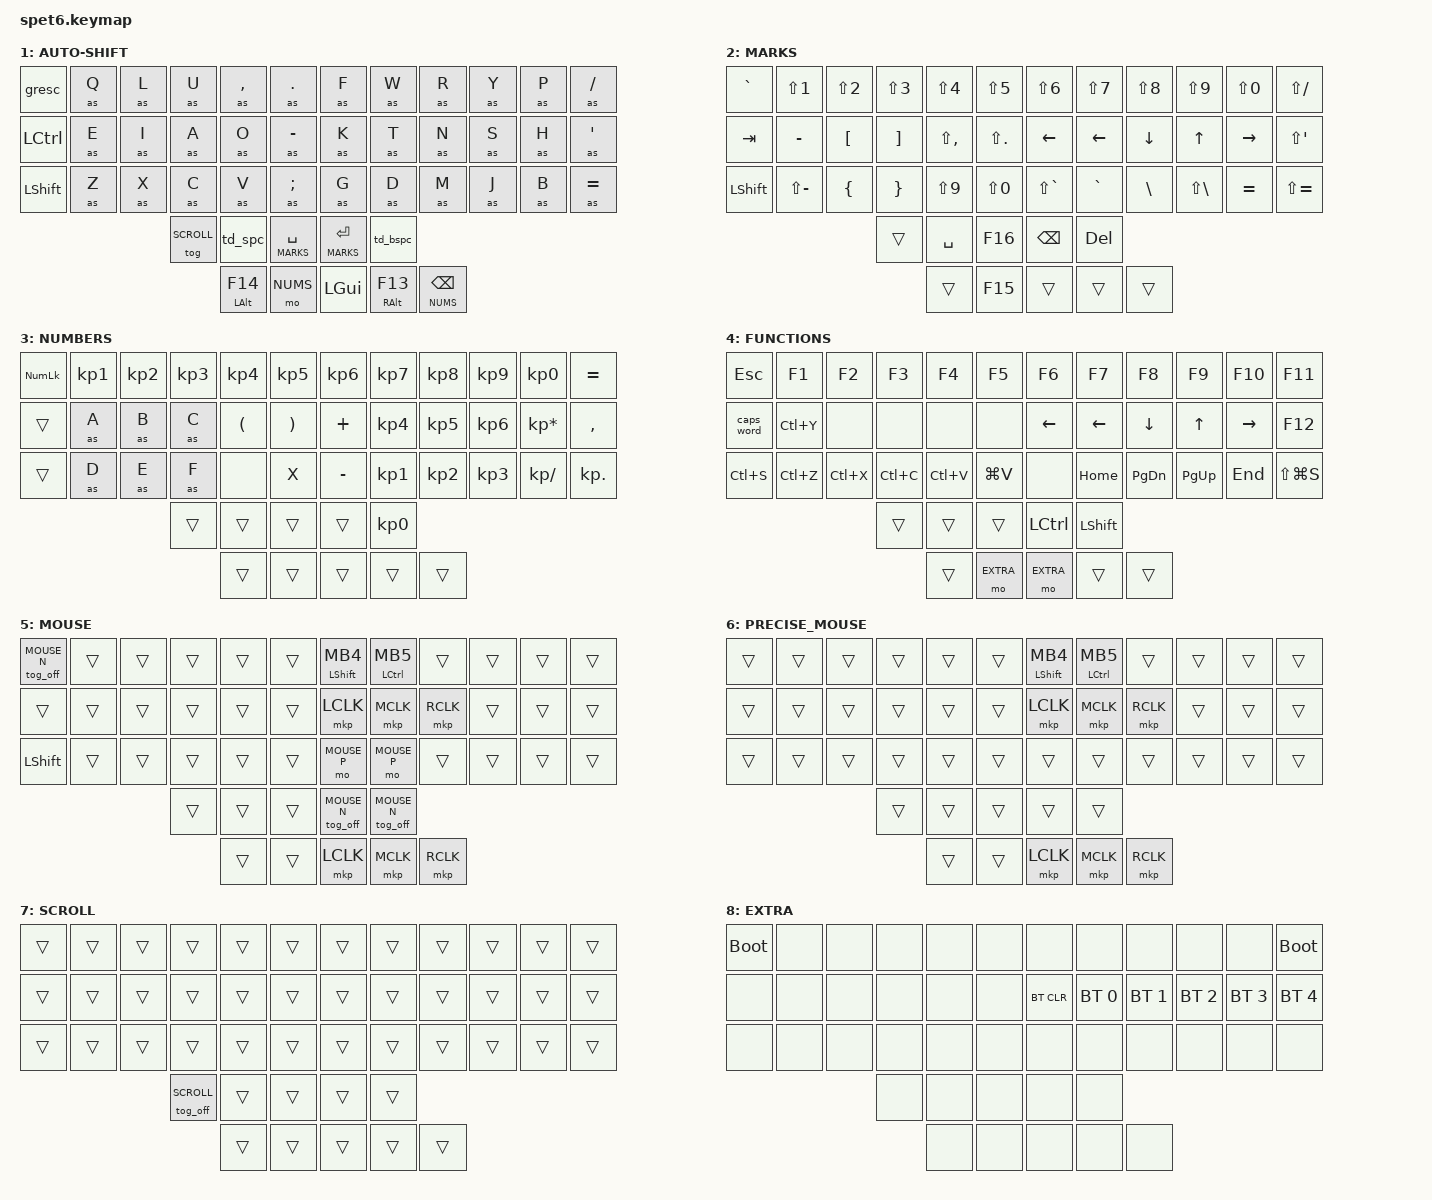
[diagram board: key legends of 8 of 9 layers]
/*
 * Copyright (c) 2020 The ZMK Contributors
 *
 * SPDX-License-Identifier: MIT
 */

#include <input/processors.dtsi>

#define ZMK_POINTING_DEFAULT_SCRL_VAL 120
#define ZMK_MOUSE_SCRL_VAL 140

#include <zephyr/dt-bindings/input/input-event-codes.h>
#include <behaviors.dtsi>
#include <dt-bindings/zmk/bt.h>
#include <dt-bindings/zmk/keys.h>
#include <dt-bindings/zmk/pointing.h>

#define DEFAULT   0
#define AUTOSHIFT 1
#define MARKS     2
#define NUMS      3
#define FUNCS     4
#define MOUSE_N   5
#define MOUSE_P   6
#define SCROLL    7
#define EXTRA     8

// OS設定を日本語キーボードのまま使用するための変換定義
#define JP_DQUOTE       AT                // "
#define JP_AMPERSAND    CARET             // &
#define JP_QUOTE        AMPERSAND         // '
#define JP_EQUAL        UNDER             // =
#define JP_CARET        EQUAL             // ^
#define JP_YEN          0x89              // ¥
#define JP_PLUS         COLON             // +
#define JP_TILDE        PLUS              // ~
#define JP_PIPE         LS(0x89)          // |
#define JP_AT           LEFT_BRACKET      // @
#define JP_COLON        SINGLE_QUOTE      // :
#define JP_ASTERISK     DOUBLE_QUOTES     // *
#define JP_BACKQUOTE    LEFT_BRACE        // `
#define JP_UNDERSCORE   LS(0x87)          // _
#define JP_LBRACKET     RIGHT_BRACKET     // [
#define JP_RBRACKET     BACKSLASH         // ]
#define JP_LPAREN       ASTERISK          // (
#define JP_RPAREN       LEFT_PARENTHESIS  // )
#define JP_LBRACE       RIGHT_BRACE       // {
#define JP_RBRACE       PIPE              // }
#define JP_KANA         LANGUAGE_1        // かな
#define JP_EISU         LANGUAGE_2        // 英数
#define JP_HANZEN       GRAVE             // 半角/全角

/**************************************************************************/
/*  TrackBall 関連                                                        */

&trackball { cpi = <600>; };

&trackball_listener {
    input-processors = <&zip_temp_layer MOUSE_N 5000>;

    precise {
        layers = <MOUSE_P>;
        input-processors = <&zip_xy_scaler 1 16>;
        process-next;
    };
};

&trackball_scroller {
    layers = <SCROLL>;

    // Example: adjust sensitivity of scroll multiply by 1 and divide by 60.
    // input-processors = <&zip_xy_scaler 1 60 &zip_xy_to_scroll_mapper>;
};

// クリック時に10秒間AMLを延長

&mkp_input_listener { input-processors = <&zip_temp_layer MOUSE_N 10000>; };

// キー入力から200ms間はAMLを抑制(AML誤発動防止)

&zip_temp_layer { require-prior-idle-ms = <200>; };

/**************************************************************************/
/*   マウススクロール用設定                                               */

/ {
    input_processors {
        zip_wheel_scaler: zip_wheel_scaler {
            compatible = "zmk,input-processor-scaler";
            #input-processor-cells = <2>;
            type = <INPUT_EV_REL>;
            codes = <INPUT_REL_WHEEL>;
            track-remainders;
        };
    };
};

&msc {
    delay-ms = <0>;
    trigger-period-ms = <10>;
    time-to-max-speed-ms = <0>;
    acceleration-exponent = <0>;
};

&msc_input_listener {
    warp {
        layers = <MOUSE_N SCROLL>;
        input-processors = <&zip_wheel_scaler 4 1>;
    };

    normal {
        layers = <DEFAULT MARKS NUMS FUNCS EXTRA>;
        input-processors = <&zip_wheel_scaler 1 1>;
    };
};

/**************************************************************************/

/ {
    combos {
        compatible = "zmk,combos";

        combo_shift_R {
            bindings = <&kp RSHFT>;
            key-positions = <39 40>;
        };

        combo_shift_L {
            bindings = <&kp LSHFT>;
            key-positions = <37 38>;
        };

        combo_tab {
            bindings = <&kp TAB>;
            key-positions = <12 13>;
        };

        mo_scroll {
            bindings = <&mo SCROLL>;
            key-positions = <41 42>;
        };

        mo_scroll2 {
            bindings = <&mo SCROLL>;
            key-positions = <30 31>;
        };

        alt_space {
            bindings = <&kp LA(SPACE)>;
            key-positions = <38 39>;
        };

        combo_capslock {
            bindings = <&kp CAPS>;
            key-positions = <12 13 14>;
        };

        toggle_autoshift {
            bindings = <&tog AUTOSHIFT>;
            key-positions = <0 11>;
        };

        Lctrl {
            bindings = <&kp LCTRL>;
            key-positions = <24 25>;
        };

        Rctrl {
            bindings = <&kp RCTRL>;
            key-positions = <34 35>;
        };

        toggle_IME {
            bindings = <&kp LC(SPACE)>;
            key-positions = <37 40>;
        };
    };

    /**************************************************************************/

    macros {
        // for Auto Shift

        shifted: macro_shifted_kp {
            #binding-cells = <1>;
            label = "MACRO_SHIFTED_KP";
            compatible = "zmk,behavior-macro-one-param";
            bindings =
                <&macro_press>,
                <&kp LSHFT &macro_param_1to1>,
                <&macro_tap>,
                <&kp MACRO_PLACEHOLDER>,
                <&macro_release>,
                <&kp LSHFT>;
        };

        as: autoshift {
            compatible = "zmk,behavior-macro-one-param";
            #binding-cells = <1>;
            label = "AUTOSHIFT_KP";
            bindings =
                <&macro_press>,
                <&macro_param_1to1 &macro_param_1to2 &as_ht MACRO_PLACEHOLDER MACRO_PLACEHOLDER>,
                <&macro_pause_for_release>,
                <&macro_release>,
                <&macro_param_1to1 &macro_param_1to2 &as_ht MACRO_PLACEHOLDER MACRO_PLACEHOLDER>;
        };
    };

    /**************************************************************************/

    behaviors {
        td_bspc: tap_dance_0 {
            compatible = "zmk,behavior-tap-dance";
            #binding-cells = <0>;
            tapping-term-ms = <200>;
            bindings = <&lt FUNCS BSPC>, <&kp BSPC>;
        };

        td_spc: tap_dance_1 {
            compatible = "zmk,behavior-tap-dance";
            #binding-cells = <0>;
            tapping-term-ms = <200>;
            bindings = <&lt FUNCS SPACE>, <&kp SPACE>;
        };

        mouse_scroll: mouse_wheel_scroll {
            compatible = "zmk,behavior-sensor-rotate-var";
            #sensor-binding-cells = <2>;
            bindings = <&msc>, <&msc>;

            tap-ms = <25>;
        };

        mod_mkp: mod_mkp {
            compatible = "zmk,behavior-hold-tap";
            label = "MOD_MKP";
            bindings = <&kp>, <&mkp>;

            #binding-cells = <2>;
            tapping-term-ms = <150>;
        };

        as_ht: autoshift_hold_tap {
            compatible = "zmk,behavior-hold-tap";
            label = "AUTOSHIFT_HOLD_TAP";
            #binding-cells = <2>;
            tapping_term_ms = <180>;
            quick_tap_ms = <0>;
            flavor = "tap-preferred";
            bindings = <&shifted>, <&kp>;
        };

        tog_off: toggle_layer_off {
            compatible = "zmk,behavior-toggle-layer";
            #binding-cells = <1>;
            display-name = "Toggle Layer Off";
            toggle-mode = "off";
        };

        ime_alt: ime_alt {
            compatible = "zmk,behavior-hold-tap";
            label = "IME_ALT";
            bindings = <&kp>, <&kp>;

            #binding-cells = <2>;
            tapping-term-ms = <200>;
            flavor = "tap-preferred";
        };
    };

    /**************************************************************************/

    keymap {
        compatible = "zmk,keymap";

        default_layer {
            display-name = "BASE";

            //               | SW2  | SW3  | SW4  | SW5  |   | SW6  | SW7  | SW8  | SW9  |
            // | SW0  | SW1  | SW14 | SW15 | SW16 | SW17 |   | SW18 | SW19 | SW20 | SW21 | SW10 | SW11 |
            // | SW12 | SW13 | SW26 | SW27 | SW28 | SW29 |   | SW30 | SW31 | SW32 | SW33 | SW22 | SW23 |
            // | SW24 | SW25 | SW38 | SW39 | SW40 | SW41 |   | SW42 | SW43 | SW44 | SW45 | SW34 | SW35 |
            // | SW36 | SW37 | SW50 | SW51 | SW52 | SW53 |   | SW54 | SW55 | SW56 | SW57 | SW46 | SW47 |
            // | SW48 | SW49 | SW60 | SW61 | SW62 | (LAJS)   (RAJS) | SW69 | SW70 | SW71 | SW58 | SW59 |
            //                                  (TouchPad)
            // 		                              | SW65 |   | SW66 |	    (TrackBall)
            // 							   | SW64 |					| SW67 |
            // | SW72 |				| SW63 |							   | SW68 |				| SW83 |
            //    (LeftRotaryEncoder)                                             (RightRotaryEncoder)
            //		  | SW73 |															 | SW78 |
            // | SW74 | SW77 | SW76 |											  | SW79 | SW82 | SW81 |
            // 		  | SW75 |															 | SW80 |

//                                                         ||
//                                                       __||__
//                                                        \  /
//                                                         \/

            // | SW0  | SW1  | SW2  | SW3  | SW4  | SW5  |   | SW6  | SW7  | SW8  | SW9  | SW10 | SW11 |
            // | SW12 | SW13 | SW14 | SW15 | SW16 | SW17 |   | SW18 | SW19 | SW20 | SW21 | SW22 | SW23 |
            // | SW24 | SW25 | SW26 | SW27 | SW28 | SW29 |   | SW30 | SW31 | SW32 | SW33 | SW34 | SW35 |
            // | SW36 | SW37 | SW38 | SW39 | SW40 | SW41 |   | SW42 | SW43 | SW44 | SW45 | SW46 | SW47 |
            // | SW48 | SW49 | SW50 | SW51 | SW52 | SW53 |   | SW54 | SW55 | SW56 | SW57 | SW58 | SW59 |
            // | SW60 | SW61 | SW62 | SW63 | SW64 | SW65 |   | SW66 | SW67 | SW68 | SW69 | SW70 | SW71 |
            // | SW72 | SW73 | SW74 | SW75 | SW76 | SW77 |   | SW78 | SW79 | SW80 | SW81 | SW82 | SW83 |

                                                          

            // -----------------------------------------------------------------------------------------
            //               |  F4  |  F5  |  F6  |  F7  |   |  F8  |  F9  | F10  | F11  |
            // | ESCP | HOME |   2  |   3  |   4  |   5  |   |   6  |   7  |   8  |   9  |  END |  DEL |
            // |  E/J |   1  |   W  |   E  |   R  |   T  |   |   Y  |   U  |   I  |   O  |   0  | BKSP |
            // |  TAB |   Q  |   S  |   D  |   F  |   G  |   |   H  |   J  |   K  |   L  |   P  | ENTR |
            // | LSft |   A  |   X  |   C  |   V  |   B  |   |   N  |   M  |   ,  |   .  |   ↑  | RSft |
            // | LAlt |   Z  |  GUI | LCtr | SPCE |                 | SPCE | RCtr |   ←  |   ↓  |   →  |
            // 		                      	
            //                                    | SPCE |   | SPCE |
            // 							   | ENTR |					| ENTR |
            // | layr |				| BKSP |							   | BKSP |				| layr |
            //
            //		  | CtrC |															 | CtrT |
            // | CtrZ | Entr | CtrY |											  | BTab | Entr | NTab |
            // 		  | CtrV |															 | CtrW |

            // -----------------------------------------------------------------------------------------
            // | ESCP | HOME |  F4  |  F5  |  F6  |  F7  |   |  F8  |  F9  | F10  | F11  |  END |  DEL |
            // |  E/J |   1  |   2  |   3  |   4  |   5  |   |   6  |   7  |   8  |   9  |   0  | BKSP |
            // |  TAB |   Q  |   W  |   E  |   R  |   T  |   |   Y  |   U  |   I  |   O  |   P  | ENTR |
            // | LSft |   A  |   S  |   D  |   F  |   G  |   |   H  |   J  |   K  |   L  |   ↑  | RSft |
            // | LAlt |   Z  |   X  |   C  |   V  |   B  |   |   N  |   M  |   ,  |   .  |   ↓  |   →  |
            // |  GUI | LCtr | SPCE | BKSP | ENTR | SPCE |   | SPCE | ENTR | BKSP | SPCE | RCtr |   ←  |
            // | layr | CtrC | CtrZ | CtrV | CtrY | Entr |   | CtrT | BTab | CtrW | NTab | CtrT | layr |

            bindings = <
&gresc         &kp HOME   &kp F4     &kp F5         &kp F6          &kp F7       &kp F8         &kp F9             &kp F10        &kp F11     &kp END    &kp DEL
&kp JP_HANZEN  &kp 1      &kp 2      &kp 3          &kp 4           &kp 5        &kp 6          &kp 7              &kp 8          &kp 9       &kp 0      &kp BACKSPACE
&kp TAB        &kp Q      &kp W      &kp E          &kp R           &kp T        &kp Y          &kp U              &kp I          &kp O       &kp P      &kp ENTER
&kp LSHFT      &kp A      &kp S      &kp D          &kp F           &kp G        &kp H          &kp J              &kp K          &kp L       &kp UP     &kp RSHFT
&kp LALT       &kp Z      &kp X      &kp C          &kp V           &kp B        &kp N          &kp M              &kp COMMA      &kp PERIOD  &kp DOWN   &kp RIGHT
&kp LGUI       &kp LCTRL  &kp SPACE  &kp BACKSPACE  &kp ENTER       &kp SPACE    &kp SPACE      &kp ENTER          &kp BACKSPACE  &kp SPACE   &kp RCTRL  &kp LEFT
            >;

            sensor-bindings = <&inc_dec_kp RIGHT LEFT>;
        };

        autoshift_layer {
            display-name = "AUTO-SHIFT";

            // -----------------------------------------------------------------------------------------
            // |  ESC |  Q  |  L  |  U  |  ,  |  .  |   |  F  |  W   |  R  |  Y  |  P  |  /   |
            // | CTRL |  E  |  I  |  A  |  O  |  -  |   |  K  |  T   |  N  |  S  |  H  |  '   |
            // | SHFT |  Z  |  X  |  C  |  V  |  B  |   |  G  |  D   |  M  |  J  |  B  |  =   |
            //        | SCRL| SPC(FUNK) | SPC(MARK) |   | ENT(MARK) | BKSP(FUNC) |
            //              |  LALT     | NUMS      |   | GUI       | RALT       | BKSP(NUM)|

            bindings = <
&gresc     &as Q  &as L  &as U        &as COMMA          &as PERIOD       &as F          &as W              &as R               &as Y  &as P  &as SLASH
&kp LCTRL  &as E  &as I  &as A        &as O              &as MINUS        &as K          &as T              &as N               &as S  &as H  &as SQT
&kp LSHFT  &as Z  &as X  &as C        &as V              &as SEMICOLON    &as G          &as D              &as M               &as J  &as B  &as EQUAL
                         &tog SCROLL  &td_spc            &lt MARKS SPACE  &lt MARKS RET  &td_bspc
                                      &ime_alt LALT F14  &mo NUMS         &kp LGUI       &ime_alt RALT F13  &lt NUMS BACKSPACE
            >;

            sensor-bindings = <&inc_dec_kp RIGHT LEFT>;
        };

        mark_layer {
            display-name = "MARKS";

            // -----------------------------------------------------------------------------------------
            // |  ~   |  !  |  @  |  #  |  $  |  %  |   |  ^  |  &  |  *  |  (        | )   | ?  |
            // | TAB  |  -  |  {  |  }  |  <  | >   |   | LFT | LFT | DWN |  UP       | RGT |  " |
            // |      |  _  |  [  |  ]  |  (  | )   |   |  `  |  ~  |  ¥  |  Lsft(¥)  |  =  |  + |
            //                    | --- |---- | ----|   | ---- | DELETE  |
            //                          |---- | ----|   | ---- |  -----  | ---- |

            bindings = <
&kp GRAVE  &kp LS(N1)     &kp LS(N2)  &kp LS(N3)  &kp LS(N4)     &kp LS(N5)      &kp LS(N6)     &kp LS(N7)  &kp LS(N8)  &kp LS(N9)    &kp LS(N0)  &kp LS(SLASH)
&kp TAB    &kp MINUS      &kp LBKT    &kp RBKT    &kp LS(COMMA)  &kp LS(PERIOD)  &kp LEFT       &kp LEFT    &kp DOWN    &kp UP        &kp RIGHT   &kp LS(SQT)
&kp LSHFT  &kp LS(MINUS)  &kp LBRC    &kp RBRC    &kp LS(N9)     &kp LS(N0)      &kp LS(GRAVE)  &kp GRAVE   &kp BSLH    &kp LS(BSLH)  &kp EQUAL   &kp LS(EQUAL)
                                      &trans      &kp SPACE      &kp F16         &kp BACKSPACE  &kp DELETE
                                                  &trans         &kp F15         &trans         &trans      &trans
            >;

            sensor-bindings = <&inc_dec_kp DOWN UP>;
        };

        num_layer {
            display-name = "NUMBERS";

            // -----------------------------------------------------------------------------------------
            // |  NUM |  1  |  2  |  3  |  4  |  5  |   |  6  |  7  |  8  |  9  |  0  |  .   |
            // | ---- |  a  |  b  |  c  |  (  |  )  |   |  +  |  4  |  5  |  6  |  *  |  ,   |
            // | ---- |  d  |  e  |  f  | --- |  x  |   |  -  |  1  |  2  |  3  |  /  |  =   |
            //                    | --- |---- | ----|   | --- | --- |
            //                          |---- | ----|   | --- | --- | --- |

            bindings = <
&kp KP_NUM  &kp KP_N1  &kp KP_N2  &kp KP_N3  &kp KP_N4             &kp KP_N5              &kp KP_N6  &kp KP_N7        &kp KP_N8  &kp KP_N9  &kp KP_N0        &kp EQUAL
&trans      &as A      &as B      &as C      &kp LEFT_PARENTHESIS  &kp RIGHT_PARENTHESIS  &kp PLUS   &kp KP_N4        &kp KP_N5  &kp KP_N6  &kp KP_ASTERISK  &kp COMMA
&trans      &as D      &as E      &as F      &none                 &kp X                  &kp MINUS  &kp KP_N1        &kp KP_N2  &kp KP_N3  &kp KP_SLASH     &kp KP_DOT
                                  &trans     &trans                &trans                 &trans     &kp KP_NUMBER_0
                                             &trans                &trans                 &trans     &trans           &trans
            >;

            sensor-bindings = <&inc_dec_kp RIGHT LEFT>;
        };

        func_layer {
            display-name = "FUNCTIONS";

            // -----------------------------------------------------------------------------------------
            // |  ESC   | F1   |  F2  |  F3  |  F4   |  F5   |     |  F6 |  F7 |  F8 |  F9 | F10  | F11        |
            // |CAPSWORD| ---  | ---- | ---- | ----- | ----  |     | LEFT| LEFT| DOWN| UP  |RIGHT | F12        |
            // |  SAVE  | UNDO | CUT  | COPY | PASTE | PASTE |     | HOME| PGUP| PGDN| END | ---- | PrintScreen|
            //                        | ---- | ----- | ----- |     | -------- | ----  | 
            //                               | ----- |Mo(BOOT)|    | Mo(BOOT) | ----- | ----- |

            bindings = <
&kp ESC     &kp F1     &kp F2     &kp F3     &kp F4     &kp F5     &kp F6     &kp F7     &kp F8     &kp F9     &kp F10    &kp F11
&caps_word  &kp LC(Y)  &none      &none      &none      &none      &kp LEFT   &kp LEFT   &kp DOWN   &kp UP     &kp RIGHT  &kp F12
&kp LC(S)   &kp LC(Z)  &kp LC(X)  &kp LC(C)  &kp LC(V)  &kp LG(V)  &none      &kp HOME   &kp PG_DN  &kp PG_UP  &kp END    &kp LS(LG(S))
                                  &trans     &trans     &trans     &kp LCTRL  &kp LSHFT
                                             &trans     &mo EXTRA  &mo EXTRA  &trans     &trans
            >;

            sensor-bindings = <&mouse_scroll SCRL_DOWN SCRL_UP>;
        };

        mouse_layer {
            display-name = "MOUSE";

            // -----------------------------------------------------------------------------------------
            // | --- | --- | --- | --- | --- | --- |   | Prev    | Next    | ---- | --- | --- | --- |
            // | --- | --- | --- | --- | --- | --- |   | LCLK    | MCLK    | RCLK | --- | --- | --- |
            // | --- | --- | --- | --- | --- | --- |   | Precise | Precise | ---- | --- | --- | --- |
            //                   | --- | --- | --- |   | ------- | ------- |
            //                         | --- | --- |   | LCLK    | MCLK    | RCLK |

            bindings = <
&tog_off MOUSE_N  &trans  &trans  &trans  &trans  &trans  &mod_mkp LEFT_SHIFT MB4  &mod_mkp LCTRL MB5  &trans     &trans  &trans  &trans
&trans            &trans  &trans  &trans  &trans  &trans  &mkp LCLK                &mkp MCLK           &mkp RCLK  &trans  &trans  &trans
&kp LSHFT         &trans  &trans  &trans  &trans  &trans  &mo MOUSE_P              &mo MOUSE_P         &trans     &trans  &trans  &trans
                                  &trans  &trans  &trans  &tog_off MOUSE_N         &tog_off MOUSE_N
                                          &trans  &trans  &mkp LCLK                &mkp MCLK           &mkp RCLK
            >;

            sensor-bindings = <&mouse_scroll SCRL_DOWN SCRL_UP>;
        };

        precise_mouse_layer {
            display-name = "PRECISE_MOUSE";

            // -----------------------------------------------------------------------------------------
            // | --- | --- | --- | --- | --- | --- |   | Prev | Next | ---- | --- | --- | --- |
            // | --- | --- | --- | --- | --- | --- |   | LCLK | MCLK | RCLK | --- | --- | --- |
            // | --- | --- | --- | --- | --- | --- |   | ---- | ---- | ---- | --- | --- | --- |
            //                   | --- | --- | --- |   | ---- | ---- |
            //                         | --- | --- |   | LCLK | MCLK | RCLK |

            bindings = <
&trans  &trans  &trans  &trans  &trans  &trans  &mod_mkp LEFT_SHIFT MB4  &mod_mkp LCTRL MB5  &trans     &trans  &trans  &trans
&trans  &trans  &trans  &trans  &trans  &trans  &mkp LCLK                &mkp MCLK           &mkp RCLK  &trans  &trans  &trans
&trans  &trans  &trans  &trans  &trans  &trans  &trans                   &trans              &trans     &trans  &trans  &trans
                        &trans  &trans  &trans  &trans                   &trans
                                &trans  &trans  &mkp LCLK                &mkp MCLK           &mkp RCLK
            >;

            sensor-bindings = <&mouse_scroll SCRL_DOWN SCRL_UP>;
        };

        scroll_layer {
            display-name = "SCROLL";

            // -----------------------------------------------------------------------------------------
            // | --- | --- | --- | ---- | --- | --- |   | --- | --- | --- | --- | --- | --- |
            // | --- | --- | --- | ---- | --- | --- |   | --- | --- | --- | --- | --- | --- |
            // | --- | --- | --- | ---- | --- | --- |   | --- | --- | --- | --- | --- | --- |
            //                   |TO DEF| --- | --- |   | --- | --- |
            //                          | --- | --- |   | --- | --- | --- |

            bindings = <
&trans  &trans  &trans  &trans           &trans  &trans  &trans  &trans  &trans  &trans  &trans  &trans
&trans  &trans  &trans  &trans           &trans  &trans  &trans  &trans  &trans  &trans  &trans  &trans
&trans  &trans  &trans  &trans           &trans  &trans  &trans  &trans  &trans  &trans  &trans  &trans
                        &tog_off SCROLL  &trans  &trans  &trans  &trans
                                         &trans  &trans  &trans  &trans  &trans
            >;

            sensor-bindings = <&mouse_scroll SCRL_RIGHT SCRL_LEFT>;
        };

        ex_layer {
            display-name = "EXTRA";

            // -----------------------------------------------------------------------------------------
            // | BOOT |    |     |     |       |     |      |     |     |     |     |     | BOOT |
            // |      |    |     |     |       |     |      |BTCLR| BT0 | BT1 | BT2 | BT3 | BT4  |
            // |      |    |     |     |       |     |      |     |     |     |     |     |      |
            //                   |     |       |     |      |     |     | 
            //                         |       |     |      |     |     |

            bindings = <
&bootloader  &none  &none  &none  &none  &none  &none       &none         &none         &none         &none         &bootloader
&none        &none  &none  &none  &none  &none  &bt BT_CLR  &bt BT_SEL 0  &bt BT_SEL 1  &bt BT_SEL 2  &bt BT_SEL 3  &bt BT_SEL 4
&none        &none  &none  &none  &none  &none  &none       &none         &none         &none         &none         &none
                           &none  &none  &none  &none       &none
                                  &none  &none  &none       &none         &none
            >;

            sensor-bindings = <&inc_dec_kp RIGHT LEFT>;
        };
    };
};
